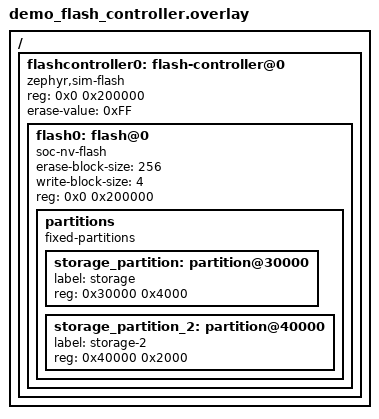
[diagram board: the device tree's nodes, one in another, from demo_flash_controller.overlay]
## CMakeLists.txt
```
# SPDX-License-Identifier: Apache-2.0

cmake_minimum_required(VERSION 3.20.0)

# Check whether the mandatory variables have been defined
if(NOT DEFINED FACTORY_BINARY_DIR)
  message(FATAL_ERROR "You must specify the FACTORY_BINARY_DIR variable, \
  see README for an example.")
endif()
if(NOT DEFINED FACTORY_NVS_CONTENT_FILE)
  message(FATAL_ERROR "You must specify the FACTORY_NVS_CONTENT_FILE variable, \
  see README for an example.")
endif()
if(NOT DEFINED FACTORY_NVS_OUTPUT_FILE)
  message(FATAL_ERROR "You must specify the FACTORY_NVS_OUTPUT_FILE variable, \
  see README for an example.")
endif()
if(NOT DEFINED FACTORY_NVS_PARTITION_DT_LABEL)
  message(FATAL_ERROR "You must specify the FACTORY_NVS_PARTITION_DT_LABEL variable, \
  see README for an example.")
endif()
if(NOT DEFINED FACTORY_NVS_LINKER_SECTION)
  message(FATAL_ERROR "You must specify the FACTORY_NVS_LINKER_SECTION variable, \
  see README for an example.")
endif()
if(NOT DEFINED FACTORY_FLASH_ERASE_VALUE)
  message(FATAL_ERROR "You must specify the FACTORY_FLASH_ERASE_VALUE variable, \
  see README for an example.")
endif()
if(NOT DEFINED FACTORY_FLASH_ERASE_BLOCK_SIZE)
  message(FATAL_ERROR "You must specify the FACTORY_FLASH_ERASE_BLOCK_SIZE variable, \
  see README for an example.")
endif()
if(NOT DEFINED FACTORY_FLASH_WRITE_BLOCK_SIZE)
  message(FATAL_ERROR "You must specify the FACTORY_FLASH_WRITE_BLOCK_SIZE variable, \
  see README for an example.")
endif()
if(NOT DEFINED FACTORY_NVS_PARTITION_SIZE)
  message(FATAL_ERROR "You must specify the FACTORY_NVS_PARTITION_SIZE variable, \
  see README for an example.")
endif()

file(WRITE ${FACTORY_BINARY_DIR}/generated_flash_controller.overlay
"/*
 * This file is automatically generated, do not modify
 */

/ {
        /* Entirely specify the flash controller 0 with the factory target board settings */
        flashcontroller0: flash-controller@0 {
                compatible = \"zephyr,sim-flash\";
                reg = < 0x0 0x200000 >;
                #address-cells = < 0x1 >;
                #size-cells = < 0x1 >;
                erase-value = < ${FACTORY_FLASH_ERASE_VALUE} >;
                flash0: flash@0 {
                        status = \"okay\";
                        compatible = \"soc-nv-flash\";
                        erase-block-size = < ${FACTORY_FLASH_ERASE_BLOCK_SIZE} >;
                        write-block-size = < ${FACTORY_FLASH_WRITE_BLOCK_SIZE} >;
                        reg = < 0x0 ${FACTORY_NVS_PARTITION_SIZE} >;
                        partitions {
                                compatible = \"fixed-partitions\";
                                #address-cells = < 0x1 >;
                                #size-cells = < 0x1 >;
                                ${FACTORY_NVS_PARTITION_DT_LABEL}: partition@0 {
                                        label = \"storage\";
                                        reg = < 0x0 ${FACTORY_NVS_PARTITION_SIZE} >;
                                };
                        };
                };
        };
};
"
)

set(DTC_OVERLAY_FILE
  remove_default_flash_controller.overlay
  ${FACTORY_BINARY_DIR}/generated_flash_controller.overlay
)

find_package(Zephyr REQUIRED HINTS $ENV{ZEPHYR_BASE})
project(nvs)

target_sources(app PRIVATE src/main.c ${FACTORY_NVS_CONTENT_FILE})
target_compile_definitions(app PRIVATE FACTORY_NVS_PARTITION_DT_LABEL=${FACTORY_NVS_PARTITION_DT_LABEL})
target_include_directories(app PRIVATE include)

enable_testing()
add_test(NAME generate_nvs COMMAND bash -c "\
  zephyr/zephyr.exe --flash=${FACTORY_BINARY_DIR}/nvs_area.bin && \
  mkdir -p $(dirname ${FACTORY_NVS_OUTPUT_FILE}) && \
  xxd -i ${FACTORY_BINARY_DIR}/nvs_area.bin > ${FACTORY_NVS_OUTPUT_FILE} && \
  sed -i -e '1d' ${FACTORY_NVS_OUTPUT_FILE} && \
  sed -i -e '1i __in_section(${FACTORY_NVS_LINKER_SECTION}, static, var) unsigned char nvs_${FACTORY_NVS_PARTITION_DT_LABEL}[] = {' ${FACTORY_NVS_OUTPUT_FILE} \
  "
)
```

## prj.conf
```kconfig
CONFIG_FLASH=y
CONFIG_FLASH_SIMULATOR=y
CONFIG_NVS=y
CONFIG_LOG=y
CONFIG_LOG_MODE_IMMEDIATE=y
CONFIG_NVS_LOG_LEVEL_DBG=y
```

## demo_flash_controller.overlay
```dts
/*
 * Copyright (C) 2024 BayLibre.
 *
 * SPDX-License-Identifier: Apache-2.0
 */

/ {
	/* Entirely specify the flash controller 0 with the factory target board settings */
	flashcontroller0: flash-controller@0 {
		compatible = "zephyr,sim-flash";
		reg = < 0x0 0x200000 >;
		#address-cells = < 0x1 >;
		#size-cells = < 0x1 >;
		erase-value = < 0xFF >;
		flash0: flash@0 {
			status = "okay";
			compatible = "soc-nv-flash";
			erase-block-size = < 256 >;
			write-block-size = < 4 >;
			reg = < 0x0 0x200000 >;
			partitions {
				compatible = "fixed-partitions";
				#address-cells = < 0x1 >;
				#size-cells = < 0x1 >;
				storage_partition: partition@30000 {
					label = "storage";
					reg = < 0x30000 0x4000 >;
				};
				storage_partition_2: partition@40000 {
					label = "storage-2";
					reg = < 0x40000 0x2000 >;
				};
			};
		};
	};
};
```

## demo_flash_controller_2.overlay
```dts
/*
 * Copyright (C) 2024 BayLibre.
 *
 * SPDX-License-Identifier: Apache-2.0
 */

/ {
	/* Entirely specify the flash controller 0 with the factory target board settings */
	flashcontroller0: flash-controller@0 {
		compatible = "zephyr,sim-flash";
		reg = < 0x0 0x200000 >;
		#address-cells = < 0x1 >;
		#size-cells = < 0x1 >;
		erase-value = < 0xFF >;
		flash0: flash@0 {
			status = "okay";
			compatible = "soc-nv-flash";
			erase-block-size = < 0x1000 >;
			write-block-size = < 0x1 >;
			reg = < 0x0 0x6000 >;
			partitions {
				compatible = "fixed-partitions";
				#address-cells = < 0x1 >;
				#size-cells = < 0x1 >;
				storage_partition: partition@0 {
					label = "storage";
					reg = < 0x0 0x6000 >;
				};
			};
		};
	};
};
```

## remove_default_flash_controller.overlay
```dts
/*
 * Copyright (C) 2024 BayLibre.
 *
 * SPDX-License-Identifier: Apache-2.0
 */

/ {
	chosen {
		/delete-property/ zephyr,code-partition;
	};
	/delete-node/ flash-controller@0;
};
```

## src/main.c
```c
#include <zephyr/drivers/flash.h>
#include <zephyr/storage/flash_map.h>
#include <zephyr/fs/nvs.h>

#include "nsi_cmdline.h"

// TEST
#define NVS_PARTITION		storage_partition
#define NVS_PARTITION_DEVICE	FIXED_PARTITION_DEVICE(NVS_PARTITION)
#define NVS_PARTITION_OFFSET	FIXED_PARTITION_OFFSET(NVS_PARTITION)

int main(void)
{
	struct nvs_fs fs;
	struct flash_pages_info flash_info;
	int ret;
	int argc; char **argv;

	nsi_get_test_cmd_line_args(&argc, &argv);
	printk("argc=%d\n", argc);
	for (ret = 0; ret < argc; ret++) {
		printk("arg %d = %s\n", ret, argv[ret]);
	}

	fs.flash_device = NVS_PARTITION_DEVICE;
	if (!device_is_ready(fs.flash_device)) {
		printk("Flash device %s is not ready\n", fs.flash_device->name);
		return 0;
	}
	fs.offset = NVS_PARTITION_OFFSET;
	ret = flash_get_page_info_by_offs(fs.flash_device, fs.offset, &flash_info);
	if (ret) {
		printk("Unable to get page info\n");
		return 0;
	}
	fs.sector_size = flash_info.size;
	fs.sector_count = 3U;

	ret = nvs_mount(&fs);
	if (ret) {
		printk("Flash Init failed\n");
		return 0;
	}

	return 0;
}
```

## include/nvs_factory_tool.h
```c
/*
 * Copyright (C) 2024 BayLibre.
 *
 * SPDX-License-Identifier: Apache-2.0
 */

#ifndef H_NVS_FACTORY_TOOL_H
#define H_NVS_FACTORY_TOOL_H

#include <stddef.h>
#include <stdint.h>

struct nvs_factory_tool_item_t {
	uint16_t id;
	const void *data;
	uint16_t size;
};

extern struct nvs_factory_tool_item_t nvs_factory_tool_items[];
extern size_t nvs_factory_tool_items_count;

#endif
```

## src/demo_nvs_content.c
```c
/*
 * Copyright (C) 2024 BayLibre.
 *
 * SPDX-License-Identifier: Apache-2.0
 */

#include <nvs_factory_tool.h>

uint16_t item_id_0_data = 0x1234;
uint32_t item_id_3_data = 0x5678;
uint8_t item_id_27349_data[] = { 0xAA, 0xBB, 0xCC, 0xDD, 0xEE, 0xFF };

struct nvs_factory_tool_item_t nvs_factory_tool_items[] = {
	{ 12, "test string", sizeof("test string") },
	{ 3, &item_id_3_data, sizeof(item_id_3_data) },
	{ 0, &item_id_0_data, sizeof(item_id_0_data) },
	{ 27349, &item_id_27349_data, sizeof(item_id_27349_data) }
};

size_t nvs_factory_tool_items_count = sizeof(nvs_factory_tool_items) /
				      sizeof(struct nvs_factory_tool_item_t);
```
